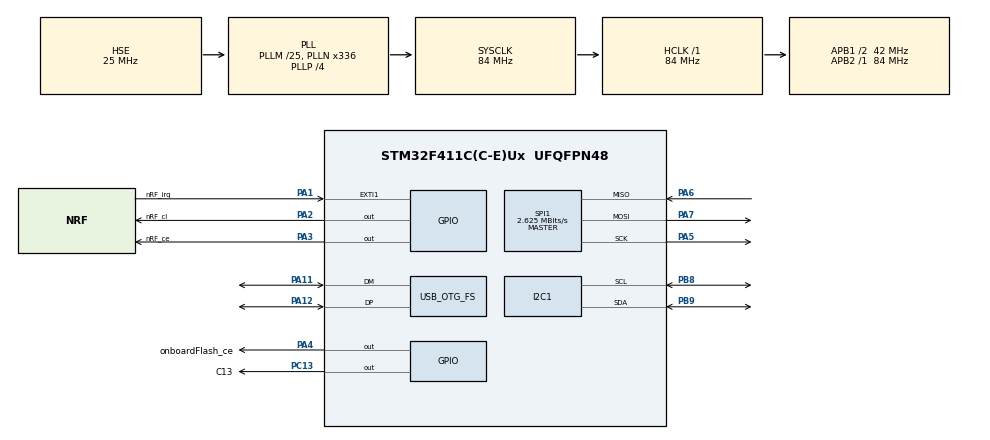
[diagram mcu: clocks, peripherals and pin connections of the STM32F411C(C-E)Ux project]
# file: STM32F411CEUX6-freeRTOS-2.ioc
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Dma.Request0=SPI1_RX
Dma.SPI1_RX.0.Direction=DMA_PERIPH_TO_MEMORY
Dma.SPI1_RX.0.FIFOMode=DMA_FIFOMODE_ENABLE
Dma.SPI1_RX.0.FIFOThreshold=DMA_FIFO_THRESHOLD_FULL
Dma.SPI1_RX.0.Instance=DMA2_Stream0
Dma.SPI1_RX.0.MemBurst=DMA_MBURST_SINGLE
Dma.SPI1_RX.0.MemDataAlignment=DMA_MDATAALIGN_HALFWORD
Dma.SPI1_RX.0.MemInc=DMA_MINC_ENABLE
Dma.SPI1_RX.0.Mode=DMA_NORMAL
Dma.SPI1_RX.0.PeriphBurst=DMA_PBURST_SINGLE
Dma.SPI1_RX.0.PeriphDataAlignment=DMA_PDATAALIGN_HALFWORD
Dma.SPI1_RX.0.PeriphInc=DMA_PINC_DISABLE
Dma.SPI1_RX.0.Priority=DMA_PRIORITY_LOW
FREERTOS.Mutexes01=i2c_1Mutex,Static,myMutex01ControlBlock,Available
FREERTOS.Queues01=displayQueue,80,char,0,Dynamic,NULL,NULL
FREERTOS.Tasks01=defaultTask,24,128,StartDefaultTask,As weak,NULL,Dynamic,NULL,NULL;BlinkTask,8,128,BlinkTask_Start,As weak,NULL,Dynamic,NULL,NULL;DisplayTask,8,128,DisplayTask_Start,As weak,NULL,Dynamic,NULL,NULL
FREERTOS.configENABLE_FPU=0
I2C1.DutyCycle=I2C_DUTYCYCLE_16_9
I2C1.I2C_Mode=I2C_Fast
Mcu.Family=STM32F4
Mcu.Name=STM32F411C(C-E)Ux
Mcu.Package=UFQFPN48
NVIC.DMA2_Stream0_IRQn=true\:5\:0\:false\:false\:true\:true\:false\:true\:true
NVIC.EXTI1_IRQn=true\:5\:0\:false\:false\:true\:true\:true\:true\:true
NVIC.OTG_FS_IRQn=true\:5\:0\:false\:false\:true\:true\:false\:true\:true
NVIC.PriorityGroup=NVIC_PRIORITYGROUP_4
NVIC.TIM1_UP_TIM10_IRQn=true\:15\:0\:false\:false\:true\:false\:false\:true\:true
NVIC.TimeBase=TIM1_UP_TIM10_IRQn
NVIC.TimeBaseIP=TIM10
PA1.GPIO_Label=nRF_irq
PA1.GPIO_ModeDefaultEXTI=GPIO_MODE_IT_FALLING
PA1.GPIO_PuPd=GPIO_PULLUP
PA1.Signal=GPXTI1
PA11.Mode=Device_Only
PA11.Signal=USB_OTG_FS_DM
PA12.Mode=Device_Only
PA12.Signal=USB_OTG_FS_DP
PA13.Signal=SYS_JTMS-SWDIO
PA14.Signal=SYS_JTCK-SWCLK
PA2.GPIO_Label=nRF_cl
PA2.Signal=GPIO_Output
PA3.GPIO_Label=nRF_ce
PA3.Signal=GPIO_Output
PA4.GPIO_Label=onboardFlash_ce
PA4.Signal=GPIO_Output
PA5.Mode=Full_Duplex_Master
PA5.Signal=SPI1_SCK
PA6.Mode=Full_Duplex_Master
PA6.Signal=SPI1_MISO
PA7.Mode=Full_Duplex_Master
PA7.Signal=SPI1_MOSI
PB10.Signal=I2C2_SCL
PB8.GPIO_Pu=GPIO_PULLUP
PB8.GPIO_Speed=GPIO_SPEED_FREQ_MEDIUM
PB8.Mode=I2C
PB8.Signal=I2C1_SCL
PB9.GPIO_Pu=GPIO_PULLUP
PB9.GPIO_Speed=GPIO_SPEED_FREQ_MEDIUM
PB9.Mode=I2C
PB9.Signal=I2C1_SDA
PC13-ANTI_TAMP.GPIO_Label=C13
PC13-ANTI_TAMP.Signal=GPIO_Output
PC14-OSC32_IN.Mode=LSE-External-Oscillator
PC14-OSC32_IN.Signal=RCC_OSC32_IN
PC15-OSC32_OUT.Mode=LSE-External-Oscillator
PC15-OSC32_OUT.Signal=RCC_OSC32_OUT
PH0\ -\ OSC_IN.Mode=HSE-External-Oscillator
PH0\ -\ OSC_IN.Signal=RCC_OSC_IN
PH1\ -\ OSC_OUT.Mode=HSE-External-Oscillator
PH1\ -\ OSC_OUT.Signal=RCC_OSC_OUT
ProjectManager.HeapSize=0x200
ProjectManager.StackSize=0x400
ProjectManager.TargetToolchain=Makefile
RCC.48MHZClocksFreq_Value=48000000
RCC.AHBFreq_Value=84000000
RCC.APB1CLKDivider=RCC_HCLK_DIV2
RCC.APB1Freq_Value=42000000
RCC.APB1TimCLKDivider=2
RCC.APB1TimFreq_Value=84000000
RCC.APB2Freq_Value=84000000
RCC.APB2TimFreq_Value=84000000
RCC.CortexFreq_Value=84000000
RCC.HCLKFreq_Value=84000000
RCC.HSE_VALUE=25000000
RCC.HSI_VALUE=16000000
RCC.PLLM=25
RCC.PLLN=336
RCC.PLLP=RCC_PLLP_DIV4
RCC.PLLQ=7
RCC.SYSCLKFreq_VALUE=84000000
RCC.SYSCLKSource=RCC_SYSCLKSOURCE_PLLCLK
RCC.VCOOutputFreq_Value=336000000
SPI1.BaudRatePrescaler=SPI_BAUDRATEPRESCALER_32
SPI1.CalculateBaudRate=2.625 MBits/s
SPI1.Direction=SPI_DIRECTION_2LINES
SPI1.Mode=SPI_MODE_MASTER
SPI1.VirtualType=VM_MASTER
USB_DEVICE.CLASS_NAME_FS=CDC
USB_DEVICE.VirtualMode=Cdc
USB_DEVICE.VirtualModeFS=Cdc_FS
USB_OTG_FS.VirtualMode=Device_Only
VP_CRC_VS_CRC.Mode=CRC_Activate
VP_FREERTOS_VS_CMSIS_V2.Mode=CMSIS_V2
VP_SYS_VS_tim10.Mode=TIM10
VP_USB_DEVICE_VS_USB_DEVICE_CDC_FS.Mode=CDC_FS
board=custom

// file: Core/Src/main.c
/* USER CODE BEGIN Header */
/**
  ******************************************************************************
  * @file           : main.c
  * @brief          : Main program body
  ******************************************************************************
  * @attention
  *
  * Copyright (c) 2025 STMicroelectronics.
  * All rights reserved.
  *
  * This software is licensed under terms that can be found in the LICENSE file
  * in the root directory of this software component.
  * If no LICENSE file comes with this software, it is provided AS-IS.
  *
  ******************************************************************************
  */
/* USER CODE END Header */
#include "main.h"
#include "cmsis_os.h"
#include "usb_device.h"

typedef StaticSemaphore_t osStaticMutexDef_t;

CRC_HandleTypeDef hcrc;

I2C_HandleTypeDef hi2c1;

SPI_HandleTypeDef hspi1;

/* Definitions for defaultTask */
osThreadId_t defaultTaskHandle;
const osThreadAttr_t defaultTask_attributes = {
  .name = "defaultTask",
  .stack_size = 128 * 4,
  .priority = (osPriority_t) osPriorityNormal,
};
/* Definitions for BlinkTask */
osThreadId_t BlinkTaskHandle;
const osThreadAttr_t BlinkTask_attributes = {
  .name = "BlinkTask",
  .stack_size = 128 * 4,
  .priority = (osPriority_t) osPriorityLow,
};
/* Definitions for DisplayTask */
osThreadId_t DisplayTaskHandle;
const osThreadAttr_t DisplayTask_attributes = {
  .name = "DisplayTask",
  .stack_size = 128 * 4,
  .priority = (osPriority_t) osPriorityLow,
};
/* Definitions for displayQueue */
osMessageQueueId_t displayQueueHandle;
const osMessageQueueAttr_t displayQueue_attributes = {
  .name = "displayQueue"
};
/* Definitions for i2c_1Mutex */
osMutexId_t i2c_1MutexHandle;
osStaticMutexDef_t myMutex01ControlBlock;
const osMutexAttr_t i2c_1Mutex_attributes = {
  .name = "i2c_1Mutex",
  .cb_mem = &myMutex01ControlBlock,
  .cb_size = sizeof(myMutex01ControlBlock),
};

void SystemClock_Config(void);
static void MX_GPIO_Init(void);
void StartDefaultTask(void *argument);
void BlinkTask_Start(void *argument);
void DisplayTask_Start(void *argument);

int main(void)
{

  /* MCU Configuration--------------------------------------------------------*/

  /* Reset of all peripherals, Initializes the Flash interface and the Systick. */
  HAL_Init();

  /* Configure the system clock */
  SystemClock_Config();

  /* Initialize all configured peripherals */
  MX_GPIO_Init();
  MX_I2C1_Init();
  MX_SPI1_Init();
  MX_CRC_Init();

  /* Init scheduler */
  osKernelInitialize();
  /* Create the mutex(es) */
  /* creation of i2c_1Mutex */
  i2c_1MutexHandle = osMutexNew(&i2c_1Mutex_attributes);

  /* Create the queue(s) */
  /* creation of displayQueue */
  displayQueueHandle = osMessageQueueNew (2, sizeof(DisplayMessage), &displayQueue_attributes);

  /* Create the thread(s) */
  /* creation of defaultTask */
  defaultTaskHandle = osThreadNew(StartDefaultTask, NULL, &defaultTask_attributes);

  /* creation of BlinkTask */
  BlinkTaskHandle = osThreadNew(BlinkTask_Start, NULL, &BlinkTask_attributes);

  /* creation of DisplayTask */
  DisplayTaskHandle = osThreadNew(DisplayTask_Start, NULL, &DisplayTask_attributes);

  /* Start scheduler */
  osKernelStart();

  /* We should never get here as control is now taken by the scheduler */

  /* Infinite loop */
  while (1)
  {

  }
}

void SystemClock_Config(void)
{
  RCC_OscInitTypeDef RCC_OscInitStruct = {0};
  RCC_ClkInitTypeDef RCC_ClkInitStruct = {0};

  /** Configure the main internal regulator output voltage
  */
  __HAL_RCC_PWR_CLK_ENABLE();
  __HAL_PWR_VOLTAGESCALING_CONFIG(PWR_REGULATOR_VOLTAGE_SCALE1);

  /** Initializes the RCC Oscillators according to the specified parameters
  * in the RCC_OscInitTypeDef structure.
  */
  RCC_OscInitStruct.OscillatorType = RCC_OSCILLATORTYPE_HSE;
  RCC_OscInitStruct.HSEState = RCC_HSE_ON;
  RCC_OscInitStruct.PLL.PLLState = RCC_PLL_ON;
  RCC_OscInitStruct.PLL.PLLSource = RCC_PLLSOURCE_HSE;
  RCC_OscInitStruct.PLL.PLLM = 25;
  RCC_OscInitStruct.PLL.PLLN = 336;
  RCC_OscInitStruct.PLL.PLLP = RCC_PLLP_DIV4;
  RCC_OscInitStruct.PLL.PLLQ = 7;
  if (HAL_RCC_OscConfig(&RCC_OscInitStruct) != HAL_OK)
  {
    Error_Handler();
  }

  /** Initializes the CPU, AHB and APB buses clocks
  */
  RCC_ClkInitStruct.ClockType = RCC_CLOCKTYPE_HCLK|RCC_CLOCKTYPE_SYSCLK
                              |RCC_CLOCKTYPE_PCLK1|RCC_CLOCKTYPE_PCLK2;
  RCC_ClkInitStruct.SYSCLKSource = RCC_SYSCLKSOURCE_PLLCLK;
  RCC_ClkInitStruct.AHBCLKDivider = RCC_SYSCLK_DIV1;
  RCC_ClkInitStruct.APB1CLKDivider = RCC_HCLK_DIV2;
  RCC_ClkInitStruct.APB2CLKDivider = RCC_HCLK_DIV1;

  if (HAL_RCC_ClockConfig(&RCC_ClkInitStruct, FLASH_LATENCY_2) != HAL_OK)
  {
    Error_Handler();
  }
}

void MX_CRC_Init(void)
{

  hcrc.Instance = CRC;
  if (HAL_CRC_Init(&hcrc) != HAL_OK)
  {
    Error_Handler();
  }

}

void MX_I2C1_Init(void)
{

  hi2c1.Instance = I2C1;
  hi2c1.Init.ClockSpeed = 400000;
  hi2c1.Init.DutyCycle = I2C_DUTYCYCLE_16_9;
  hi2c1.Init.OwnAddress1 = 0;
  hi2c1.Init.AddressingMode = I2C_ADDRESSINGMODE_7BIT;
  hi2c1.Init.DualAddressMode = I2C_DUALADDRESS_DISABLE;
  hi2c1.Init.OwnAddress2 = 0;
  hi2c1.Init.GeneralCallMode = I2C_GENERALCALL_DISABLE;
  hi2c1.Init.NoStretchMode = I2C_NOSTRETCH_DISABLE;
  if (HAL_I2C_Init(&hi2c1) != HAL_OK)
  {
    Error_Handler();
  }

}

void MX_SPI1_Init(void)
{

  /* SPI1 parameter configuration*/
  hspi1.Instance = SPI1;
  hspi1.Init.Mode = SPI_MODE_MASTER;
  hspi1.Init.Direction = SPI_DIRECTION_2LINES;
  hspi1.Init.DataSize = SPI_DATASIZE_8BIT;
  hspi1.Init.CLKPolarity = SPI_POLARITY_LOW;
  hspi1.Init.CLKPhase = SPI_PHASE_1EDGE;
  hspi1.Init.NSS = SPI_NSS_SOFT;
  hspi1.Init.BaudRatePrescaler = SPI_BAUDRATEPRESCALER_32;
  hspi1.Init.FirstBit = SPI_FIRSTBIT_MSB;
  hspi1.Init.TIMode = SPI_TIMODE_DISABLE;
  hspi1.Init.CRCCalculation = SPI_CRCCALCULATION_DISABLE;
  hspi1.Init.CRCPolynomial = 10;
  if (HAL_SPI_Init(&hspi1) != HAL_OK)
  {
    Error_Handler();
  }

}

static void MX_GPIO_Init(void)
{
  GPIO_InitTypeDef GPIO_InitStruct = {0};

  /* GPIO Ports Clock Enable */
  __HAL_RCC_GPIOC_CLK_ENABLE();
  __HAL_RCC_GPIOH_CLK_ENABLE();
  __HAL_RCC_GPIOA_CLK_ENABLE();
  __HAL_RCC_GPIOB_CLK_ENABLE();

  /*Configure GPIO pin Output Level */
  HAL_GPIO_WritePin(C13_GPIO_Port, C13_Pin, GPIO_PIN_RESET);

  /*Configure GPIO pin Output Level */
  HAL_GPIO_WritePin(GPIOA, nRF_cl_Pin|nRF_ce_Pin|onboardFlash_ce_Pin, GPIO_PIN_RESET);

  /*Configure GPIO pin : C13_Pin */
  GPIO_InitStruct.Pin = C13_Pin;
  GPIO_InitStruct.Mode = GPIO_MODE_OUTPUT_PP;
  GPIO_InitStruct.Pull = GPIO_NOPULL;
  GPIO_InitStruct.Speed = GPIO_SPEED_FREQ_LOW;
  HAL_GPIO_Init(C13_GPIO_Port, &GPIO_InitStruct);

  /*Configure GPIO pins : PA0 PA8 PA9 PA10
                           PA15 */
  GPIO_InitStruct.Pin = GPIO_PIN_0|GPIO_PIN_8|GPIO_PIN_9|GPIO_PIN_10
                          |GPIO_PIN_15;
  GPIO_InitStruct.Mode = GPIO_MODE_ANALOG;
  GPIO_InitStruct.Pull = GPIO_NOPULL;
  HAL_GPIO_Init(GPIOA, &GPIO_InitStruct);

  /*Configure GPIO pin : nRF_irq_Pin */
  GPIO_InitStruct.Pin = nRF_irq_Pin;
  GPIO_InitStruct.Mode = GPIO_MODE_IT_FALLING;
  GPIO_InitStruct.Pull = GPIO_PULLUP;
  HAL_GPIO_Init(nRF_irq_GPIO_Port, &GPIO_InitStruct);

  /*Configure GPIO pins : nRF_cl_Pin nRF_ce_Pin onboardFlash_ce_Pin */
  GPIO_InitStruct.Pin = nRF_cl_Pin|nRF_ce_Pin|onboardFlash_ce_Pin;
  GPIO_InitStruct.Mode = GPIO_MODE_OUTPUT_PP;
  GPIO_InitStruct.Pull = GPIO_NOPULL;
  GPIO_InitStruct.Speed = GPIO_SPEED_FREQ_LOW;
  HAL_GPIO_Init(GPIOA, &GPIO_InitStruct);

  /*Configure GPIO pins : PB0 PB1 PB2 PB10
                           PB12 PB13 PB14 PB15
                           PB3 PB4 PB5 PB6
                           PB7 */
  GPIO_InitStruct.Pin = GPIO_PIN_0|GPIO_PIN_1|GPIO_PIN_2|GPIO_PIN_10
                          |GPIO_PIN_12|GPIO_PIN_13|GPIO_PIN_14|GPIO_PIN_15
                          |GPIO_PIN_3|GPIO_PIN_4|GPIO_PIN_5|GPIO_PIN_6
                          |GPIO_PIN_7;
  GPIO_InitStruct.Mode = GPIO_MODE_ANALOG;
  GPIO_InitStruct.Pull = GPIO_NOPULL;
  HAL_GPIO_Init(GPIOB, &GPIO_InitStruct);

  /* EXTI interrupt init*/
  HAL_NVIC_SetPriority(EXTI1_IRQn, 5, 0);
  HAL_NVIC_EnableIRQ(EXTI1_IRQn);

}

/* USER CODE BEGIN 4 */

static const struct DisplayMessage_t default_message = {"Hello", "LUNA!"};

/* USER CODE END 4 */

__weak void StartDefaultTask(void *argument)
{
  /* init code for USB_DEVICE */
  MX_USB_DEVICE_Init();
  /* USER CODE BEGIN 5 */
  /* Infinite loop */

  osDelay(500);
  osMessageQueuePut(displayQueueHandle,&default_message,( TickType_t ) 10,0);
  for(;;)
  {
    osDelay(1);
  }
  /* USER CODE END 5 */
}

void HAL_TIM_PeriodElapsedCallback(TIM_HandleTypeDef *htim)
{
  if (htim->Instance == TIM10)
  {
    HAL_IncTick();
  }
}

void Error_Handler(void)
{
  __disable_irq();
  while (1)
  {
  }
}
